# DMASS_INTAGGR_0_INTAGGR_L2G_48120000h register map
Vendor: Texas Instruments
Peripheral module from a debugger description file (folder AM275x).
Registers are 64-bit, read-write, reset 0xFFFF unless marked. A register's access mark holds for its fields unless they carry their own. Offsets are as the file gives them; lines under a group give offsets from that group; [hi:lo] are bit positions; {n}, {i} and the like mark numbered series; 'fields as' and 'values as' point back to an identical list; <NAME> marks a mode.

## intaggr_l2g
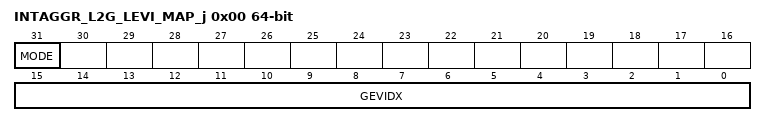
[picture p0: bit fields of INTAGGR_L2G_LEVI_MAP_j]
0x00 INTAGGR_L2G_LEVI_MAP_j — This register determines how the ordinal local event is translated to a global event on the outgoing event transport lane. Both pulse and rising edge local event types are supported. With pulsed events, the event count is determined by the number of cycles for which the event signal remains high. For rising edge events, the count represents the total number of rising edge transitions. The index field of the register determines the outgoing global event index, and the mode bit specifies either pulsed or rising edge local event detection.
  [31] MODE — Local event detection mode. This field is set to 0 for pulsed events, and to 1 for rising edge eventss Reset Source: srst_n
  [15:0] GEVIDX — Global event index. This field specifies the index of the outgoing global event. Set to 0xFFFF to disable. Reset Source: srst_n
